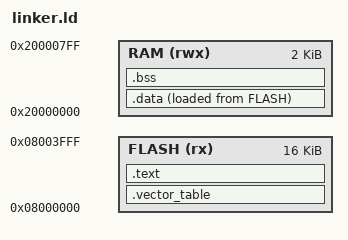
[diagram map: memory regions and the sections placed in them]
MEMORY
{
    FLASH (rx) : ORIGIN = 0x08000000, LENGTH = 16K
    RAM (rwx)  : ORIGIN = 0x20000000, LENGTH = 2K
}

SECTIONS
{
    .vector_table :
    {
        . = ALIGN(4);
        KEEP(*(.vector_table))
        . = ALIGN(4);
    } > FLASH

    .text :
    {
        . = ALIGN(4);
        *(.text .text.*)
        *(.rodata .rodata.*)
        . = ALIGN(4);
    } > FLASH

    .data :
    {
        . = ALIGN(4);
        _sdata = .;
        *(.data .data.*)
        *(.sdata .sdata.*)
        . = ALIGN(4);
        _edata = .;
    } > RAM AT > FLASH

    _sidata = LOADADDR(.data);

    .bss (NOLOAD) :
    {
        . = ALIGN(4);
        _sbss = .;
        *(.bss .bss.*)
        *(.sbss .sbss.*)
        *(COMMON)
        . = ALIGN(4);
        _ebss = .;
    } > RAM

    PROVIDE(__global_pointer$ = ORIGIN(RAM) + 0x800);
    PROVIDE(_stack_top = ORIGIN(RAM) + LENGTH(RAM));

    /DISCARD/ :
    {
        *(.eh_frame*)
        *(.comment)
        *(.note*)
    }
}
